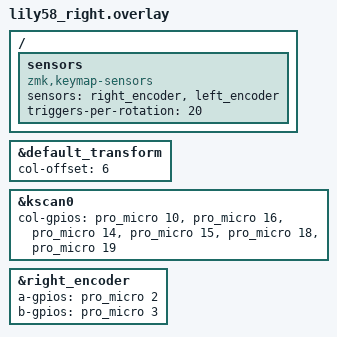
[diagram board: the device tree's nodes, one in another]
/* boards/shields/lily58/lily58_right.overlay */
#include "lily58.dtsi"

&default_transform {
    col-offset = <6>;
};

&kscan0 {
    col-gpios
        = <&pro_micro 10 GPIO_ACTIVE_HIGH>
        , <&pro_micro 16 GPIO_ACTIVE_HIGH>
        , <&pro_micro 14 GPIO_ACTIVE_HIGH>
        , <&pro_micro 15 GPIO_ACTIVE_HIGH>
        , <&pro_micro 18 GPIO_ACTIVE_HIGH>
        , <&pro_micro 19 GPIO_ACTIVE_HIGH>
        ;
};

&right_encoder {
    status = "okay";
    /* Override the bad pins from dtsi (Pin 4 conflict) */
    /* We assume the encoder is installed in the OLED header slots (Pins 2 & 3) */
    a-gpios = <&pro_micro 2 (GPIO_ACTIVE_HIGH | GPIO_PULL_UP)>;
    b-gpios = <&pro_micro 3 (GPIO_ACTIVE_HIGH | GPIO_PULL_UP)>;
};

/ {
    sensors {
        compatible = "zmk,keymap-sensors";
        sensors = <&right_encoder &left_encoder>;
        triggers-per-rotation = <20>;
    };
};

